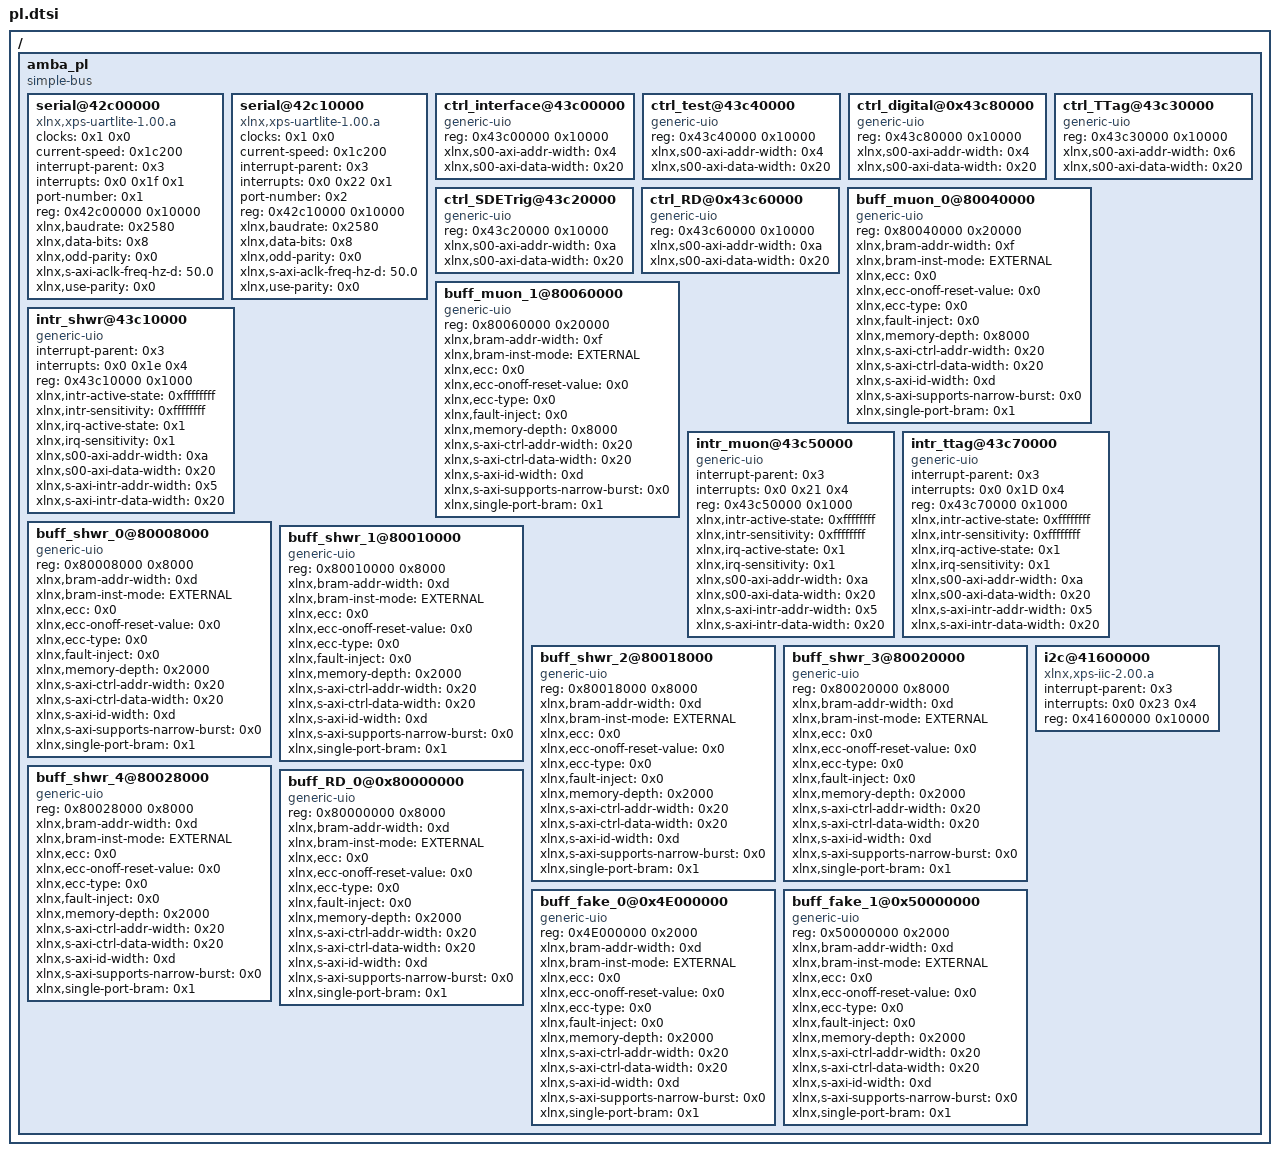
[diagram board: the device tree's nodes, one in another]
/*
 * CAUTION: This file is automatically generated by Xilinx and R.Assiro manually.
 * Version: HSI 
 * Today is: Fri Jul 19 12:18:43 2019
 * 30-mAR-2020 Delete Robertos commented out stuff so can do diff
*/


/ {
	amba_pl {
		#address-cells = <0x1>;
		#size-cells = <0x1>;
		compatible = "simple-bus";
		ranges;

		serial@42c00000 {
			clock-names = "ref_clk";
			clocks = <0x1 0x0>;
			compatible = "xlnx,xps-uartlite-1.00.a";
			current-speed = <0x1c200>;
			device_type = "serial";
			interrupt-parent = <0x3>;
			interrupts = <0x0 0x1f 0x1>;
			port-number = <0x1>;
			reg = <0x42c00000 0x10000>;
			xlnx,baudrate = <0x2580>;
			xlnx,data-bits = <0x8>;
			xlnx,odd-parity = <0x0>;
			xlnx,s-axi-aclk-freq-hz-d = "50.0";
			xlnx,use-parity = <0x0>;
		};

		serial@42c10000 {
			clock-names = "ref_clk";
			clocks = <0x1 0x0>;
			compatible = "xlnx,xps-uartlite-1.00.a";
			current-speed = <0x1c200>;
			device_type = "serial";
			interrupt-parent = <0x3>;
			interrupts = <0x0 0x22 0x1>;
			port-number = <0x2>;
			reg = <0x42c10000 0x10000>;
			xlnx,baudrate = <0x2580>;
			xlnx,data-bits = <0x8>;
			xlnx,odd-parity = <0x0>;
			xlnx,s-axi-aclk-freq-hz-d = "50.0";
			xlnx,use-parity = <0x0>;
		};

		ctrl_interface@43c00000 {
			compatible = "generic-uio";
			reg = <0x43c00000 0x10000>;
			xlnx,s00-axi-addr-width = <0x4>;
			xlnx,s00-axi-data-width = <0x20>;
		};

		ctrl_test@43c40000 {
			compatible = "generic-uio";
			reg = <0x43c40000 0x10000>;
			xlnx,s00-axi-addr-width = <0x4>;
			xlnx,s00-axi-data-width = <0x20>;
		};
                ctrl_digital@0x43c80000 {
			compatible = "generic-uio";
			reg = <0x43c80000 0x10000>;
			xlnx,s00-axi-addr-width = <0x4>;
			xlnx,s00-axi-data-width = <0x20>;                       
                };

		ctrl_TTag@43c30000 {
			compatible = "generic-uio";
			reg = <0x43c30000 0x10000>;
			xlnx,s00-axi-addr-width = <0x6>;
			xlnx,s00-axi-data-width = <0x20>;
		};
                
                ctrl_SDETrig@43c20000 {
			compatible = "generic-uio";
			reg = <0x43c20000 0x10000>;
			xlnx,s00-axi-addr-width = <0xa>;
			xlnx,s00-axi-data-width = <0x20>;
		};
                
                ctrl_RD@0x43c60000{
			compatible = "generic-uio";
			reg = <0x43c60000 0x10000>;
			xlnx,s00-axi-addr-width = <0xa>;
			xlnx,s00-axi-data-width = <0x20>;
                };

                buff_muon_0@80040000 {
			compatible = "generic-uio";
			reg = <0x80040000 0x20000>;
			xlnx,bram-addr-width = <0xf>;
			xlnx,bram-inst-mode = "EXTERNAL";
			xlnx,ecc = <0x0>;
			xlnx,ecc-onoff-reset-value = <0x0>;
			xlnx,ecc-type = <0x0>;
			xlnx,fault-inject = <0x0>;
			xlnx,memory-depth = <0x8000>;
			xlnx,s-axi-ctrl-addr-width = <0x20>;
			xlnx,s-axi-ctrl-data-width = <0x20>;
			xlnx,s-axi-id-width = <0xd>;
			xlnx,s-axi-supports-narrow-burst = <0x0>;
			xlnx,single-port-bram = <0x1>;
		};

		buff_muon_1@80060000 {
			compatible = "generic-uio";
			reg = <0x80060000 0x20000>;
			xlnx,bram-addr-width = <0xf>;
			xlnx,bram-inst-mode = "EXTERNAL";
			xlnx,ecc = <0x0>;
			xlnx,ecc-onoff-reset-value = <0x0>;
			xlnx,ecc-type = <0x0>;
			xlnx,fault-inject = <0x0>;
			xlnx,memory-depth = <0x8000>;
			xlnx,s-axi-ctrl-addr-width = <0x20>;
			xlnx,s-axi-ctrl-data-width = <0x20>;
			xlnx,s-axi-id-width = <0xd>;
			xlnx,s-axi-supports-narrow-burst = <0x0>;
			xlnx,single-port-bram = <0x1>;
		};

                intr_shwr@43c10000 {
			compatible = "generic-uio";
			interrupt-parent = <0x3>;
			interrupts = <0x0 0x1e 0x4>;
			reg = <0x43c10000 0x1000>;
			xlnx,intr-active-state = <0xffffffff>;
			xlnx,intr-sensitivity = <0xffffffff>;
			xlnx,irq-active-state = <0x1>;
			xlnx,irq-sensitivity = <0x1>;
			xlnx,s00-axi-addr-width = <0xa>;
			xlnx,s00-axi-data-width = <0x20>;
			xlnx,s-axi-intr-addr-width = <0x5>;
			xlnx,s-axi-intr-data-width = <0x20>;
		};


		intr_muon@43c50000 {
			compatible = "generic-uio";
			interrupt-parent = <0x3>;
			interrupts = <0x0 0x21 0x4>;
			reg = <0x43c50000 0x1000>;
			xlnx,intr-active-state = <0xffffffff>;
			xlnx,intr-sensitivity = <0xffffffff>;
			xlnx,irq-active-state = <0x1>;
			xlnx,irq-sensitivity = <0x1>;
			xlnx,s00-axi-addr-width = <0xa>;
			xlnx,s00-axi-data-width = <0x20>;
			xlnx,s-axi-intr-addr-width = <0x5>;
			xlnx,s-axi-intr-data-width = <0x20>;
		};

		intr_ttag@43c70000 {
			compatible = "generic-uio";
			interrupt-parent = <0x3>;
			interrupts = <0x0 0x1D 0x4>;
			reg = <0x43c70000 0x1000>;
			xlnx,intr-active-state = <0xffffffff>;
			xlnx,intr-sensitivity = <0xffffffff>;
			xlnx,irq-active-state = <0x1>;
			xlnx,irq-sensitivity = <0x1>;
			xlnx,s00-axi-addr-width = <0xa>;
			xlnx,s00-axi-data-width = <0x20>;
			xlnx,s-axi-intr-addr-width = <0x5>;
			xlnx,s-axi-intr-data-width = <0x20>;
		};


		buff_shwr_0@80008000 {
			compatible = "generic-uio";
			reg = <0x80008000 0x8000>;
			xlnx,bram-addr-width = <0xd>;
			xlnx,bram-inst-mode = "EXTERNAL";
			xlnx,ecc = <0x0>;
			xlnx,ecc-onoff-reset-value = <0x0>;
			xlnx,ecc-type = <0x0>;
			xlnx,fault-inject = <0x0>;
			xlnx,memory-depth = <0x2000>;
			xlnx,s-axi-ctrl-addr-width = <0x20>;
			xlnx,s-axi-ctrl-data-width = <0x20>;
			xlnx,s-axi-id-width = <0xd>;
			xlnx,s-axi-supports-narrow-burst = <0x0>;
			xlnx,single-port-bram = <0x1>;
		};

		buff_shwr_1@80010000 {
			compatible = "generic-uio";
			reg = <0x80010000 0x8000>;
			xlnx,bram-addr-width = <0xd>;
			xlnx,bram-inst-mode = "EXTERNAL";
			xlnx,ecc = <0x0>;
			xlnx,ecc-onoff-reset-value = <0x0>;
			xlnx,ecc-type = <0x0>;
			xlnx,fault-inject = <0x0>;
			xlnx,memory-depth = <0x2000>;
			xlnx,s-axi-ctrl-addr-width = <0x20>;
			xlnx,s-axi-ctrl-data-width = <0x20>;
			xlnx,s-axi-id-width = <0xd>;
			xlnx,s-axi-supports-narrow-burst = <0x0>;
			xlnx,single-port-bram = <0x1>;
		};

                buff_shwr_2@80018000 {
			compatible = "generic-uio";
			reg = <0x80018000 0x8000>;
			xlnx,bram-addr-width = <0xd>;
			xlnx,bram-inst-mode = "EXTERNAL";
			xlnx,ecc = <0x0>;
			xlnx,ecc-onoff-reset-value = <0x0>;
			xlnx,ecc-type = <0x0>;
			xlnx,fault-inject = <0x0>;
			xlnx,memory-depth = <0x2000>;
			xlnx,s-axi-ctrl-addr-width = <0x20>;
			xlnx,s-axi-ctrl-data-width = <0x20>;
			xlnx,s-axi-id-width = <0xd>;
			xlnx,s-axi-supports-narrow-burst = <0x0>;
			xlnx,single-port-bram = <0x1>;
		};

		buff_shwr_3@80020000 {
			compatible = "generic-uio";
			reg = <0x80020000 0x8000>;
			xlnx,bram-addr-width = <0xd>;
			xlnx,bram-inst-mode = "EXTERNAL";
			xlnx,ecc = <0x0>;
			xlnx,ecc-onoff-reset-value = <0x0>;
			xlnx,ecc-type = <0x0>;
			xlnx,fault-inject = <0x0>;
			xlnx,memory-depth = <0x2000>;
			xlnx,s-axi-ctrl-addr-width = <0x20>;
			xlnx,s-axi-ctrl-data-width = <0x20>;
			xlnx,s-axi-id-width = <0xd>;
			xlnx,s-axi-supports-narrow-burst = <0x0>;
			xlnx,single-port-bram = <0x1>;
		};

		buff_shwr_4@80028000 {
			compatible = "generic-uio";
			reg = <0x80028000 0x8000>;
			xlnx,bram-addr-width = <0xd>;
			xlnx,bram-inst-mode = "EXTERNAL";
			xlnx,ecc = <0x0>;
			xlnx,ecc-onoff-reset-value = <0x0>;
			xlnx,ecc-type = <0x0>;
			xlnx,fault-inject = <0x0>;
			xlnx,memory-depth = <0x2000>;
			xlnx,s-axi-ctrl-addr-width = <0x20>;
			xlnx,s-axi-ctrl-data-width = <0x20>;
			xlnx,s-axi-id-width = <0xd>;
			xlnx,s-axi-supports-narrow-burst = <0x0>;
			xlnx,single-port-bram = <0x1>;
		};

		buff_RD_0@0x80000000 {
			compatible = "generic-uio";
			reg = <0x80000000 0x8000>;
			xlnx,bram-addr-width = <0xd>;
			xlnx,bram-inst-mode = "EXTERNAL";
			xlnx,ecc = <0x0>;
			xlnx,ecc-onoff-reset-value = <0x0>;
			xlnx,ecc-type = <0x0>;
			xlnx,fault-inject = <0x0>;
			xlnx,memory-depth = <0x2000>;
			xlnx,s-axi-ctrl-addr-width = <0x20>;
			xlnx,s-axi-ctrl-data-width = <0x20>;
			xlnx,s-axi-id-width = <0xd>;
			xlnx,s-axi-supports-narrow-burst = <0x0>;
			xlnx,single-port-bram = <0x1>;
		};

		buff_fake_0@0x4E000000 {
			compatible = "generic-uio";
			reg = <0x4E000000 0x2000>;
			xlnx,bram-addr-width = <0xd>;
			xlnx,bram-inst-mode = "EXTERNAL";
			xlnx,ecc = <0x0>;
			xlnx,ecc-onoff-reset-value = <0x0>;
			xlnx,ecc-type = <0x0>;
			xlnx,fault-inject = <0x0>;
			xlnx,memory-depth = <0x2000>;
			xlnx,s-axi-ctrl-addr-width = <0x20>;
			xlnx,s-axi-ctrl-data-width = <0x20>;
			xlnx,s-axi-id-width = <0xd>;
			xlnx,s-axi-supports-narrow-burst = <0x0>;
			xlnx,single-port-bram = <0x1>;
		};

		buff_fake_1@0x50000000 {
			compatible = "generic-uio";
			reg = <0x50000000 0x2000>;
			xlnx,bram-addr-width = <0xd>;
			xlnx,bram-inst-mode = "EXTERNAL";
			xlnx,ecc = <0x0>;
			xlnx,ecc-onoff-reset-value = <0x0>;
			xlnx,ecc-type = <0x0>;
			xlnx,fault-inject = <0x0>;
			xlnx,memory-depth = <0x2000>;
			xlnx,s-axi-ctrl-addr-width = <0x20>;
			xlnx,s-axi-ctrl-data-width = <0x20>;
			xlnx,s-axi-id-width = <0xd>;
			xlnx,s-axi-supports-narrow-burst = <0x0>;
			xlnx,single-port-bram = <0x1>;
		};

		i2c@41600000 {
			#address-cells = <0x1>;
			#size-cells = <0x0>;
			compatible = "xlnx,xps-iic-2.00.a";
			interrupt-parent = <0x3>;
			interrupts = <0x0 0x23 0x4>;
			reg = <0x41600000 0x10000>;
		};
	};

};
